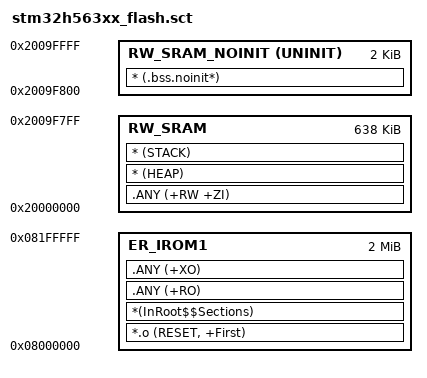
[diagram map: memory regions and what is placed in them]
; *************************************************************
; *** Scatter-Loading Description File generated by uVision ***
; *************************************************************

LR_IROM1 0x08000000 0x00200000  {    ; load region size_region
  ER_IROM1 0x08000000 0x00200000  {  ; load address = execution address
   *.o (RESET, +First)
   *(InRoot$$Sections)
   .ANY (+RO)
   .ANY (+XO)
  }
  RW_SRAM 0x20000000 0x0009F800   {  ; RW data
   .ANY (+RW +ZI)
   * (HEAP)                          ; Heap
   * (STACK)                         ; Stack
  }
  RW_SRAM_NOINIT 0x2009F800 UNINIT 0x800  {
    * (.bss.noinit*)
  }
}

